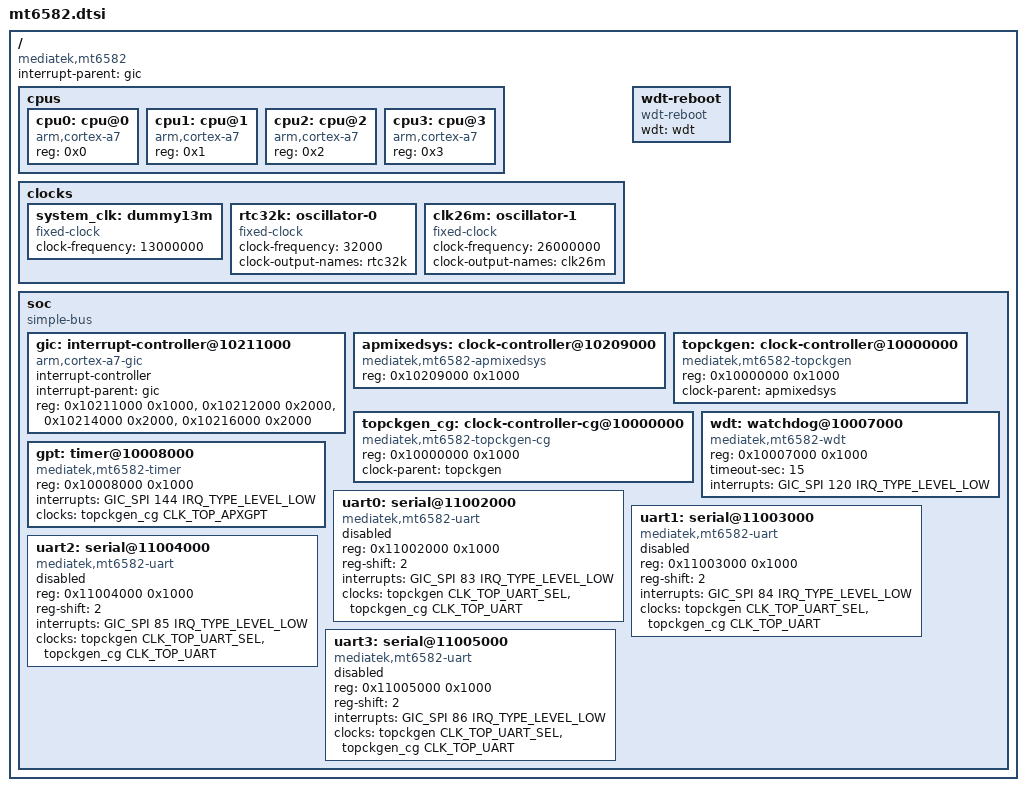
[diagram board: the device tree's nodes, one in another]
#include <dt-bindings/interrupt-controller/irq.h>
#include <dt-bindings/interrupt-controller/arm-gic.h>
#include <dt-bindings/clock/mt6582-clk.h>

/ {
	compatible = "mediatek,mt6582";
	#address-cells = <1>;
	#size-cells = <1>;
	interrupt-parent = <&gic>;

	cpus {
		#address-cells = <1>;
		#size-cells = <0>;

		cpu0: cpu@0 {
			compatible = "arm,cortex-a7";
			device_type = "cpu";
			reg = <0x0>;
		};

		cpu1: cpu@1 {
			compatible = "arm,cortex-a7";
			device_type = "cpu";
			reg = <0x1>;
		};

		cpu2: cpu@2 {
			compatible = "arm,cortex-a7";
			device_type = "cpu";
			reg = <0x2>;
		};

		cpu3: cpu@3 {
			compatible = "arm,cortex-a7";
			device_type = "cpu";
			reg = <0x3>;
		};
	};

	clocks {
		#address-cells = <1>;
		#size-cells = <1>;
		ranges;

		system_clk: dummy13m {
			compatible = "fixed-clock";
			clock-frequency = <13000000>;
			#clock-cells = <0>;
		};

		rtc32k: oscillator-0 {
			compatible = "fixed-clock";
			clock-frequency = <32000>;
			#clock-cells = <0>;
 			clock-output-names = "rtc32k";
		};

		clk26m: oscillator-1 {
			compatible = "fixed-clock";
			#clock-cells = <0>;
			clock-frequency = <26000000>;
			clock-output-names = "clk26m";
		};
	};

	wdt-reboot {
		compatible = "wdt-reboot";
		wdt = <&wdt>;
		status = "okay";
	};

	soc {
		#address-cells = <1>;
		#size-cells = <1>;
		compatible = "simple-bus";
		ranges;

		gic: interrupt-controller@10211000 {
			compatible = "arm,cortex-a7-gic";
			interrupt-controller;
			#interrupt-cells = <3>;
			interrupt-parent = <&gic>;
			reg =	<0x10211000 0x1000>,
				<0x10212000 0x2000>,
				<0x10214000 0x2000>,
				<0x10216000 0x2000>;
		};

		apmixedsys: clock-controller@10209000	 {
			compatible = "mediatek,mt6582-apmixedsys";
			reg = <0x10209000 0x1000>;
			#clock-cells = <1>;
		};

		topckgen: clock-controller@10000000 {
			compatible = "mediatek,mt6582-topckgen";
			reg = <0x10000000 0x1000>;
			clock-parent = <&apmixedsys>;
			#clock-cells = <1>;
		};

		topckgen_cg: clock-controller-cg@10000000 {
			compatible = "mediatek,mt6582-topckgen-cg";
			reg = <0x10000000 0x1000>;
			clock-parent = <&topckgen>;
			#clock-cells = <1>;
		};

		/*mmsys_cg: clock-controller-cg@14000000 {
			compatible = "mediatek,mt6572-mmsys-cg";
			reg = <0x14000000 0x1000>;
			#clock-cells = <1>;
		};*/

		wdt: watchdog@10007000 {
			compatible = "mediatek,mt6582-wdt";
			reg = <0x10007000 0x1000>;
			timeout-sec = <15>;
			interrupts = <GIC_SPI 120 IRQ_TYPE_LEVEL_LOW>;
		};

		gpt: timer@10008000 {
			compatible = "mediatek,mt6582-timer";
			reg = <0x10008000 0x1000>;
			interrupts = <GIC_SPI 144 IRQ_TYPE_LEVEL_LOW>;
			clocks = <&topckgen_cg CLK_TOP_APXGPT>;
		};

		uart0: serial@11002000 {
			compatible = "mediatek,mt6582-uart";
			reg = <0x11002000 0x1000>;
			reg-shift = <2>;
			interrupts = <GIC_SPI 83 IRQ_TYPE_LEVEL_LOW>;
			clocks =	<&topckgen CLK_TOP_UART_SEL>,
					<&topckgen_cg CLK_TOP_UART>;
			status = "disabled";
		};

		uart1: serial@11003000 {
			compatible = "mediatek,mt6582-uart";
			reg = <0x11003000 0x1000>;
			reg-shift = <2>;
			interrupts = <GIC_SPI 84 IRQ_TYPE_LEVEL_LOW>;
			clocks =	<&topckgen CLK_TOP_UART_SEL>,
					<&topckgen_cg CLK_TOP_UART>;
			status = "disabled";
		};

		uart2: serial@11004000 {
			compatible = "mediatek,mt6582-uart";
			reg = <0x11004000 0x1000>;
			reg-shift = <2>;
			interrupts = <GIC_SPI 85 IRQ_TYPE_LEVEL_LOW>;
			clocks =	<&topckgen CLK_TOP_UART_SEL>,
					<&topckgen_cg CLK_TOP_UART>;
			status = "disabled";
		};

		uart3: serial@11005000 {
			compatible = "mediatek,mt6582-uart";
			reg = <0x11005000 0x1000>;
			reg-shift = <2>;
			interrupts = <GIC_SPI 86 IRQ_TYPE_LEVEL_LOW>;
			clocks =	<&topckgen CLK_TOP_UART_SEL>,
					<&topckgen_cg CLK_TOP_UART>;
			status = "disabled";
		};

	/*    
    pinctrl: pinctrl@10005000 {
      compatible = "mediatek,mt6572-pinctrl";
      reg = <0x10005000 0x1000>,
            <0x10208000 0x1000>,
            <0x10209000 0x1000>,
            <0x1020a000 0x1000>,
            <0x1020b000 0x1000>;
      reg-names = "gpio", 
                  "iocfg_t",
                  "iocfg_b", 
                  "iocfg_l", 
                  "iocfg_r";

      gpio: gpio-controller {
        gpio-controller;
        #gpio-cells = <2>;
      };
    };
    
    pwrap: pwrap@1000f000 {
      compatible = "mediatek,mt6572-pwrap";
      reg = <0x1000f000 0x1000>;
    };
    
    mmc0: mmc@11120000 {
      compatible = "mediatek,mt6572-mmc";
      reg = <0x11120000 0x10000>;
      interrupts = <GIC_SPI 26 IRQ_TYPE_LEVEL_LOW>;
      clocks = <&topckgen_cg CLK_TOP_MSDC0>,
               <&topckgen CLK_TOP_MSDC0_SEL>;
      clock-names = "source", "hclk";
      status = "disabled";
    };

    mmc1: mmc@11130000 {
      compatible = "mediatek,mt6572-mmc";
      reg = <0x11130000 0x10000>;
      interrupts = <GIC_SPI 27 IRQ_TYPE_LEVEL_LOW>;
      clocks = <&topckgen_cg CLK_TOP_MSDC1>,
               <&topckgen CLK_TOP_MSDC1_SEL>;
      clock-names = "source", "hclk";
      status = "disabled";
    };
    */
	};
};
